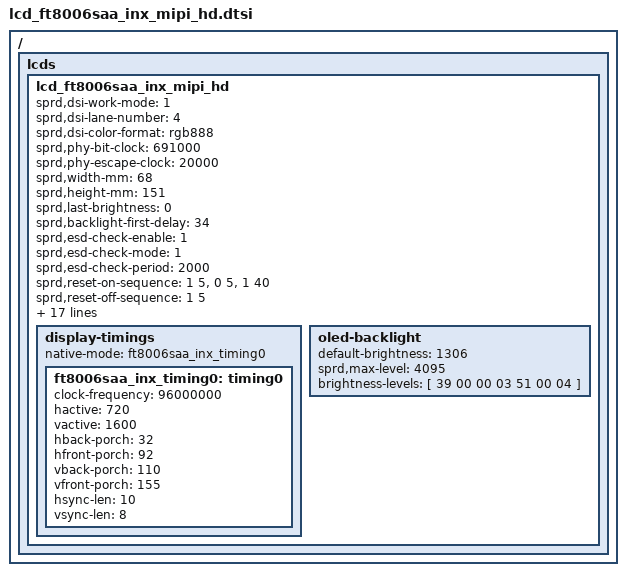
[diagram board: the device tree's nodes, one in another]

/*
 * R61350 Truly LCD config dtsi file for spreadtrum
 *
 * Copyright (C) 2018, Spreadtrum Communications Inc.
 *
 * SPDX-License-Identifier: (GPL-2.0+ OR MIT)
 */

/ {
	fragment {
		target-path = "/";
		__overlay__ {
			lcds {
				lcd_ft8006saa_inx_mipi_hd: lcd_ft8006saa_inx_mipi_hd {

					sprd,dsi-work-mode = <1>; /* video burst mode*/
					sprd,dsi-lane-number = <4>;
					sprd,dsi-color-format = "rgb888";

					sprd,phy-bit-clock = <691000>;	/* kbps */
					sprd,phy-escape-clock = <20000>;/* kHz */

					sprd,width-mm = <68>;
					sprd,height-mm = <151>;
					sprd,last-brightness = <0>;
					sprd,backlight-first-delay = <34>;

					sprd,esd-check-enable = <1>;
					sprd,esd-check-mode = <1>;
					sprd,esd-check-period = <2000>;
					/* sprd,esd-check-register = <0x0A>; */
					/* sprd,esd-check-value = <0x9C>; */

					sprd,reset-on-sequence = <1 5>, <0 5>, <1 40>;
					sprd,reset-off-sequence = <1 5>;

					sprd,power-i2c-bus = <4>;
					sprd,power-i2c-addr = <0x3e>;
					sprd,power-i2c-speed = <400000>;
					sprd,power-i2c-reg = [00 01 03];
					sprd,power-i2c-val = [12 12 03];

					sprd,use-dcs-write;
					sprd,initial-command = [
						39 00 00 02 41 5A 
						39 00 00 03 41 5A 24 
						39 00 00 02 90 5A 
						39 00 00 03 41 5A 08 
						39 00 00 04 80 C8 2C 01 
						39 00 00 03 41 5A 09 
						39 00 00 11 80 5A 51 B5 2A 6C E5 4A 01 40 62 0F 82 20 08 F0 B7 
						39 00 00 11 90 00 24 42 0A E3 91 A4 F0 9B E1 61 20 69 A1 26 00 
						39 00 00 11 A0 51 55 55 00 A0 4C 06 11 0D 60 00 FF FF 03 A5 E6 
						39 00 00 11 B0 08 3A 12 64 0B 00 00 11 00 60 00 FF FF 03 FF 34 
						39 00 00 09 C0 0C FF 18 9F 0F 00 08 00 
						39 00 00 03 41 5A 0A 
						39 00 00 11 80 FF 92 25 03 00 09 12 1D 2A 38 3B 6A 26 63 D1 99 
						39 00 00 11 90 A6 73 6B 58 43 2F 1C 09 00 09 12 1D 2A 38 3B 6A 
						39 00 00 0E A0 26 63 D1 99 A6 73 6B 58 43 2F 1C 09 00 
						39 00 00 03 41 5A 0B 
						39 00 00 11 80 00 00 20 44 08 00 60 47 00 00 10 22 04 00 B0 23 
						39 00 00 03 90 15 00 
						39 00 00 03 41 5A 0C 
						39 00 00 11 80 BA 68 68 01 32 4B D0 07 00 60 15 00 50 15 56 51 
						39 00 00 11 90 15 55 61 15 00 60 15 00 50 15 56 51 15 55 61 95 
						39 00 00 11 A0 AB 18 00 05 00 05 00 05 00 49 29 84 52 01 09 00 
						39 00 00 03 B0 00 00 
						39 00 00 03 41 5A 0D 
						39 00 00 08 80 F0 B1 71 EF 4B C0 80 
						39 00 00 03 41 5A 0E 
						39 00 00 09 80 FF 01 55 55 32 88 88 1C 
						39 00 00 03 41 5A 0F 
						39 00 00 11 80 D1 07 7C A0 11 A0 63 08 52 51 58 49 03 52 4C 4C 
						39 00 00 11 90 68 68 68 4C 4C 7C 14 00 20 06 C2 00 04 06 0C 00 
						39 00 00 05 A0 00 92 00 00 
						39 00 00 03 41 5A 10 
						39 00 00 11 80 00 00 03 E7 1F 17 10 48 80 AA D0 18 30 88 41 8A 
						39 00 00 10 90 39 28 A9 C5 9A 7B F0 07 7E E0 07 7E 20 10 00 
						39 00 00 03 41 5A 11 
						39 00 00 11 80 46 77 03 40 CA F3 FF 83 40 08 C4 06 A1 D8 24 18 
						39 00 00 11 90 30 C6 66 C1 80 39 15 CB E5 D2 68 6C 36 1D 04 C8 
						39 00 00 11 A0 B0 D9 88 60 B0 81 40 1A 1B 48 63 03 B9 00 1C 80 
						39 00 00 11 B0 50 30 00 E0 E1 01 00 28 0E 06 03 11 51 51 55 CD 
						39 00 00 11 C0 14 11 91 90 88 10 09 09 88 C6 E3 81 00 20 80 21 
						39 00 00 11 D0 42 88 00 00 00 00 00 00 00 32 04 41 26 01 12 20 
						39 00 00 11 E0 01 92 24 01 92 04 00 00 20 01 92 04 00 85 11 0C 
						39 00 00 10 F0 00 00 40 00 00 00 00 5E 4A 01 78 00 08 00 00 
						39 00 00 03 41 5A 12 
						39 00 00 11 80 00 00 00 00 00 02 03 00 00 00 00 02 03 01 41 37 
						39 00 00 11 90 F1 E7 00 00 00 00 00 00 00 00 00 00 00 2D 23 05 
						39 00 00 08 A0 FB 08 2D 23 05 FB 0C 
						39 00 00 03 41 5A 13 
						39 00 00 11 80 FD 0F 00 0C 00 00 00 00 01 08 01 1C 44 0C CE E7 
						39 00 00 0F 90 62 0E 24 98 AC 21 01 00 D0 93 24 49 06 20 
						39 00 00 03 41 5A 14 
						39 00 00 11 80 01 02 41 36 E9 EF F7 FB FD 7E 01 00 00 90 C5 84 
						39 00 00 11 90 02 4F 20 1E 14 78 02 5B A0 C0 13 D8 04 05 9E 00 
						39 00 00 11 A0 00 FC 7E 00 00 E0 F7 03 00 20 8B B5 E2 F7 47 20 
						39 00 00 11 B0 D8 89 DF 1F 01 00 10 00 00 54 32 25 2B 00 40 A1 
						39 00 00 11 C0 50 B8 0B 0A 3C 81 51 1C 77 40 81 27 30 8A E3 16 
						39 00 00 11 D0 28 F0 04 46 71 DC 06 05 9E C0 28 8E 5B A1 C0 13 
						39 00 00 11 E0 18 C5 71 3B 14 78 02 A3 38 5C 84 02 4F 60 14 87 
						39 00 00 11 F0 AB 50 E0 09 8C E2 18 01 BF DF 08 00 00 00 00 00 
						39 00 00 03 41 5A 15 
						39 00 00 11 80 00 00 00 00 00 00 00 00 00 00 00 00 52 D9 E0 F7 
						39 00 00 11 90 A3 00 20 63 C5 A8 C5 07 C9 90 5D 31 6A F1 41 8C 
						39 00 00 11 A0 78 00 00 00 00 00 00 00 00 00 00 00 00 00 00 00 
						39 00 00 11 B0 00 00 00 00 00 00 00 C0 13 00 F0 00 94 D6 34 2D 
						39 00 00 11 C0 AE 0B 86 E2 48 16 A9 6D DB B6 6D DB B6 6D DB B6 
						39 00 00 11 D0 6D DB B6 6D DB B6 6D DB B6 6D DB B6 6D DB D6 34 
						39 00 00 11 E0 29 AE 03 04 C2 40 14 A8 6D DB B6 6D DB B6 6D DB 
						39 00 00 11 F0 B6 6D DB B6 6D DB B6 6D DB B6 6D DB B6 6D 5B 92 
						39 00 00 03 41 5A 16 
						39 00 00 11 80 82 82 82 02 00 00 00 00 00 00 00 00 00 00 00 00 
						39 00 00 07 90 00 00 00 00 F0 20 
						39 00 00 03 41 5A 18 
						39 00 00 11 80 EF BD F7 DE 7B EF BD 07 08 08 0A 0C 0C 0C 0C 0C 
						39 00 00 11 90 0C 0C 0C 5C 09 A8 AA AA AA AA AA AA AA AA AA 5A 
						39 00 00 11 A0 59 59 59 59 59 59 59 59 59 59 59 09 04 FF 00 80 
						39 00 00 10 B0 80 00 04 20 00 01 08 40 00 02 10 80 00 04 00 
						39 00 00 03 41 5A 19 
						39 00 00 11 80 80 91 A3 A7 A3 A2 9E 99 93 8E 89 84 77 87 F2 FF 
						39 00 00 11 90 FF 6F F6 EF BF AF 0F FF AF B5 71 0E 6C 4A 69 08 
						39 00 00 05 A0 00 00 56 00 
						39 00 00 03 41 5A 1A 
						39 00 00 11 80 00 04 08 0C 00 10 14 18 1C 00 20 28 30 38 00 40 
						39 00 00 11 90 48 50 58 00 60 68 70 78 00 80 88 90 98 00 A0 A8 
						39 00 00 11 A0 B0 B8 00 C0 C8 D0 D8 00 E0 E8 F0 F8 00 FC FE FF 
						39 00 00 11 B0 00 00 04 08 0C 00 10 14 18 1C 00 20 28 30 38 00 
						39 00 00 11 C0 40 48 50 58 00 60 68 70 78 00 80 88 90 98 00 A0 
						39 00 00 11 D0 A8 B0 B8 00 C0 C8 D0 D8 00 E0 E8 F0 F8 00 FC FE 
						39 00 00 11 E0 FF 00 00 04 08 0C 00 10 14 18 1C 00 20 28 30 38 
						39 00 00 11 F0 00 40 48 50 58 00 60 68 70 78 00 80 88 90 98 00 
						39 00 00 03 41 5A 1B 
						39 00 00 11 80 A0 A8 B0 B8 00 C0 C8 D0 D8 00 E0 E8 F0 F8 00 FC 
						39 00 00 05 90 FE FF 00 00 
						39 00 00 03 41 5A 20 
						39 00 00 08 80 74 00 00 00 00 00 00 
						39 00 00 03 41 5A 22 
						39 00 00 0E 80 2D D3 00 55 55 55 55 55 55 55 55 9F 00 
						39 00 00 03 41 5A 23 
						39 00 00 11 80 01 05 00 05 00 00 00 00 00 00 00 00 00 00 00 00 
						39 00 00 0D 90 FF 0F 00 00 00 03 00 00 00 FF 07 35 
						39 00 00 03 41 5A 24 
						39 00 00 11 80 00 03 00 FF FF 20 00 00 00 00 00 00 00 00 3C 9C 
						39 00 00 11 90 5A 5A 5A 55 00 00 00 00 00 00 00 00 00 00 00 00 
						39 00 00 02 42 24 
						39 00 00 02 90 00 
						39 00 00 03 41 5A 2F 
						39 00 00 02 19 00 
						39 00 00 02 4C 03 
						05 78 00 01 11 
						05 00 00 01 29 
						39 00 00 03 51 00 00 
						39 00 00 02 53 2C 
						39 0A 00 02 55 00 
						];

					sprd,sleep-in-command = [
						15 5A 00 01 28
						15 64 00 01 10
						29 00 00 02 17 5A
						29 14 00 02 18 5A
						];

					sprd,sleep-out-command = [
						15 78 00 01 11
						15 14 00 01 29
						];


					sprd,cabc-off-command = [
						23 00 00 02 55 00
						];
					sprd,cabc-ui-command = [
						23 00 00 02 55 01
						];
					sprd,cabc-still-image-command = [
						23 00 00 02 55 02
						];
					sprd,cabc-video-command = [
						23 00 00 02 55 03
						];

					display-timings {
						native-mode = <&ft8006saa_inx_timing0>;

						ft8006saa_inx_timing0: timing0 {
							clock-frequency = <96000000>;
							hactive = <720>;
							vactive = <1600>;
							hback-porch = <32>;
							hfront-porch = <92>;
							vback-porch = <110>;
							vfront-porch = <155>;
							hsync-len = <10>;
							vsync-len = <8>;
						};
					};

					oled-backlight {
						default-brightness = <1306>;
						sprd,max-level = <4095>;
						brightness-levels = [
							39 00 00 03 51 00 04
						];
					};
				};
			};
		};
	};
};
